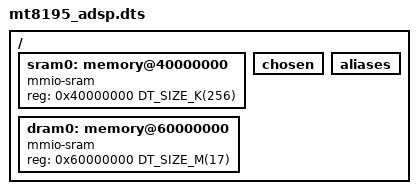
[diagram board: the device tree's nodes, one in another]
#include <mem.h>

/dts-v1/;

/ {
    #address-cells = <1>;
    #size-cells = <1>;

    sram0: memory@40000000 {
        device_type = "memory";
	compatible = "mmio-sram";
	reg = <0x40000000 DT_SIZE_K(256)>;
    };

    dram0: memory@60000000 {
        device_type = "memory";
	compatible = "mmio-sram";
	reg = <0x60000000 DT_SIZE_M(17)>;
    };

    chosen { };
    aliases { };
};
